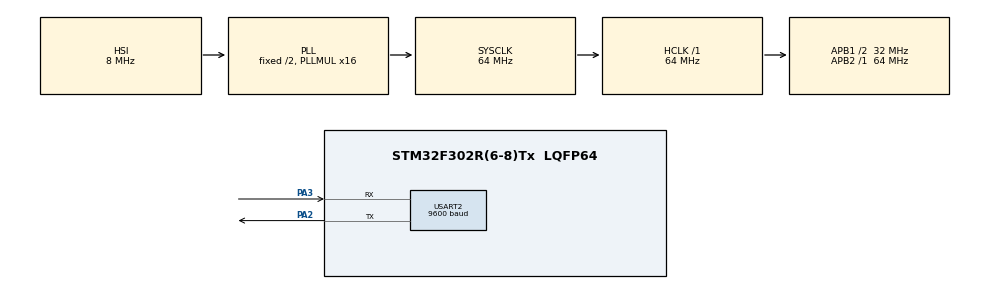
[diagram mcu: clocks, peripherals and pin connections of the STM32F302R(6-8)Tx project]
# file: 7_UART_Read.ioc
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Mcu.Family=STM32F3
Mcu.Name=STM32F302R(6-8)Tx
Mcu.Package=LQFP64
NVIC.PriorityGroup=NVIC_PRIORITYGROUP_0
PA2.Mode=Asynchronous
PA2.Signal=USART2_TX
PA3.Mode=Asynchronous
PA3.Signal=USART2_RX
PF0-OSC_IN.Mode=HSE-External-Oscillator
PF0-OSC_IN.Signal=RCC_OSC_IN
PF1-OSC_OUT.Mode=HSE-External-Oscillator
PF1-OSC_OUT.Signal=RCC_OSC_OUT
ProjectManager.HeapSize=0x200
ProjectManager.StackSize=0x400
ProjectManager.TargetToolchain=MDK-ARM V5
RCC.AHBFreq_Value=64000000
RCC.APB1CLKDivider=RCC_HCLK_DIV2
RCC.APB1Freq_Value=32000000
RCC.APB1TimFreq_Value=64000000
RCC.APB2Freq_Value=64000000
RCC.APB2TimFreq_Value=64000000
RCC.CortexFreq_Value=64000000
RCC.HCLKFreq_Value=64000000
RCC.HSE_VALUE=8000000
RCC.HSI_VALUE=8000000
RCC.LSE_VALUE=32768
RCC.PLLM=8
RCC.PLLMUL=RCC_PLL_MUL16
RCC.PLLN=336
RCC.PLLP=RCC_PLLP_DIV4
RCC.PLLQ=7
RCC.RCC_PLLsource_Clock_Source_FROM_HSE=RCC_HSE_PREDIV_DIV2
RCC.SYSCLKFreq_VALUE=64000000
RCC.SYSCLKSourceVirtual=RCC_SYSCLKSOURCE_PLLCLK
RCC.USBFreq_Value=64000000
USART2.BaudRate=9600
USART2.VirtualMode-Asynchronous=VM_ASYNC
board=NUCLEO-F302R8

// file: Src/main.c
/**
  ******************************************************************************
  * @file           : main.c
  * @brief          : Main program body
  ******************************************************************************
  ** This notice applies to any and all portions of this file
  * that are not between comment pairs USER CODE BEGIN and
  * USER CODE END. Other portions of this file, whether
  * inserted by the user or by software development tools
  * are owned by their respective copyright owners.
  *
  * COPYRIGHT(c) 2018 STMicroelectronics
  *
  * Redistribution and use in source and binary forms, with or without modification,
  * are permitted provided that the following conditions are met:
  *   1. Redistributions of source code must retain the above copyright notice,
  *      this list of conditions and the following disclaimer.
  *   2. Redistributions in binary form must reproduce the above copyright notice,
  *      this list of conditions and the following disclaimer in the documentation
  *      and/or other materials provided with the distribution.
  *   3. Neither the name of STMicroelectronics nor the names of its contributors
  *      may be used to endorse or promote products derived from this software
  *      without specific prior written permission.
  *
  * THIS SOFTWARE IS PROVIDED BY THE COPYRIGHT HOLDERS AND CONTRIBUTORS "AS IS"
  * AND ANY EXPRESS OR IMPLIED WARRANTIES, INCLUDING, BUT NOT LIMITED TO, THE
  * IMPLIED WARRANTIES OF MERCHANTABILITY AND FITNESS FOR A PARTICULAR PURPOSE ARE
  * DISCLAIMED. IN NO EVENT SHALL THE COPYRIGHT HOLDER OR CONTRIBUTORS BE LIABLE
  * FOR ANY DIRECT, INDIRECT, INCIDENTAL, SPECIAL, EXEMPLARY, OR CONSEQUENTIAL
  * DAMAGES (INCLUDING, BUT NOT LIMITED TO, PROCUREMENT OF SUBSTITUTE GOODS OR
  * SERVICES; LOSS OF USE, DATA, OR PROFITS; OR BUSINESS INTERRUPTION) HOWEVER
  * CAUSED AND ON ANY THEORY OF LIABILITY, WHETHER IN CONTRACT, STRICT LIABILITY,
  * OR TORT (INCLUDING NEGLIGENCE OR OTHERWISE) ARISING IN ANY WAY OUT OF THE USE
  * OF THIS SOFTWARE, EVEN IF ADVISED OF THE POSSIBILITY OF SUCH DAMAGE.
  *
  ******************************************************************************
  */
#include "main.h"
#include "stm32f3xx_hal.h"

uint32_t txData[10];
uint32_t rxData[10];

UART_HandleTypeDef huart2;

/* USER CODE BEGIN PV */
/* Private variables ---------------------------------------------------------*/

/* USER CODE END PV */

void SystemClock_Config(void);
static void MX_GPIO_Init(void);
static void MX_USART2_UART_Init(void);

/* USER CODE BEGIN PFP */
/* Private function prototypes -----------------------------------------------*/

/* USER CODE END PFP */
#ifdef __GNUC__
	#define PUTCHAR_PROTOTYPE int __io_putchar(&ch)
#else
	#define PUTCHAR_PROTOTYPE int fputc(int ch, FILE *f)
#endif
/* USER CODE BEGIN 0 */
PUTCHAR_PROTOTYPE
	{
		HAL_UART_Transmit(&huart2, (uint8_t *)&ch, 1, 0xFFFF);
		return ch;
	}
/* USER CODE BEGIN 0 */

/* USER CODE END 0 */

int main(void)
{

  /* MCU Configuration----------------------------------------------------------*/

  /* Reset of all peripherals, Initializes the Flash interface and the Systick. */
  HAL_Init();

  /* Configure the system clock */
  SystemClock_Config();

  /* Initialize all configured peripherals */
  MX_GPIO_Init();
  MX_USART2_UART_Init();

  /* Infinite loop */
  while (1)
  {
		HAL_UART_Receive(&huart2, (uint8_t *)rxData, 10, 10);
		//HAL_Delay(250);
		HAL_UART_Transmit(&huart2, (uint8_t *)rxData, 1, 10);
		printf("%d\n\r", rxData);

  }

}

void SystemClock_Config(void)
{

  RCC_OscInitTypeDef RCC_OscInitStruct;
  RCC_ClkInitTypeDef RCC_ClkInitStruct;

    /**Initializes the CPU, AHB and APB busses clocks
    */
  RCC_OscInitStruct.OscillatorType = RCC_OSCILLATORTYPE_HSI;
  RCC_OscInitStruct.HSIState = RCC_HSI_ON;
  RCC_OscInitStruct.HSICalibrationValue = 16;
  RCC_OscInitStruct.PLL.PLLState = RCC_PLL_ON;
  RCC_OscInitStruct.PLL.PLLSource = RCC_PLLSOURCE_HSI;
  RCC_OscInitStruct.PLL.PLLMUL = RCC_PLL_MUL16;
  if (HAL_RCC_OscConfig(&RCC_OscInitStruct) != HAL_OK)
  {
    _Error_Handler(__FILE__, __LINE__);
  }

    /**Initializes the CPU, AHB and APB busses clocks
    */
  RCC_ClkInitStruct.ClockType = RCC_CLOCKTYPE_HCLK|RCC_CLOCKTYPE_SYSCLK
                              |RCC_CLOCKTYPE_PCLK1|RCC_CLOCKTYPE_PCLK2;
  RCC_ClkInitStruct.SYSCLKSource = RCC_SYSCLKSOURCE_PLLCLK;
  RCC_ClkInitStruct.AHBCLKDivider = RCC_SYSCLK_DIV1;
  RCC_ClkInitStruct.APB1CLKDivider = RCC_HCLK_DIV2;
  RCC_ClkInitStruct.APB2CLKDivider = RCC_HCLK_DIV1;

  if (HAL_RCC_ClockConfig(&RCC_ClkInitStruct, FLASH_LATENCY_2) != HAL_OK)
  {
    _Error_Handler(__FILE__, __LINE__);
  }

    /**Configure the Systick interrupt time
    */
  HAL_SYSTICK_Config(HAL_RCC_GetHCLKFreq()/1000);

    /**Configure the Systick
    */
  HAL_SYSTICK_CLKSourceConfig(SYSTICK_CLKSOURCE_HCLK);

  /* SysTick_IRQn interrupt configuration */
  HAL_NVIC_SetPriority(SysTick_IRQn, 0, 0);
}

/* USART2 init function */
static void MX_USART2_UART_Init(void)
{

  huart2.Instance = USART2;
  huart2.Init.BaudRate = 9600;
  huart2.Init.WordLength = UART_WORDLENGTH_8B;
  huart2.Init.StopBits = UART_STOPBITS_1;
  huart2.Init.Parity = UART_PARITY_NONE;
  huart2.Init.Mode = UART_MODE_TX_RX;
  huart2.Init.HwFlowCtl = UART_HWCONTROL_NONE;
  huart2.Init.OverSampling = UART_OVERSAMPLING_16;
  huart2.Init.OneBitSampling = UART_ONE_BIT_SAMPLE_DISABLE;
  huart2.AdvancedInit.AdvFeatureInit = UART_ADVFEATURE_NO_INIT;
  if (HAL_UART_Init(&huart2) != HAL_OK)
  {
    _Error_Handler(__FILE__, __LINE__);
  }

}

/** Configure pins as
        * Analog
        * Input
        * Output
        * EVENT_OUT
        * EXTI
*/
static void MX_GPIO_Init(void)
{

  /* GPIO Ports Clock Enable */
  __HAL_RCC_GPIOF_CLK_ENABLE();
  __HAL_RCC_GPIOA_CLK_ENABLE();

}

void _Error_Handler(char *file, int line)
{
  while(1)
  {
  }
}

/************************ (C) COPYRIGHT STMicroelectronics *****END OF FILE****/
